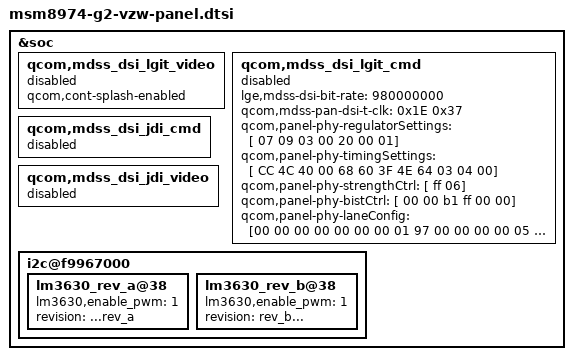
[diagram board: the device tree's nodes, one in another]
/* Copyright (c) 2012, Code Aurora Forum. All rights reserved.
 *
 * This program is free software; you can redistribute it and/or modify
 * it under the terms of the GNU General Public License version 2 and
 * only version 2 as published by the Free Software Foundation.
 *
 * This program is distributed in the hope that it will be useful,
 * but WITHOUT ANY WARRANTY; without even the implied warranty of
 * MERCHANTABILITY or FITNESS FOR A PARTICULAR PURPOSE.  See the
 * GNU General Public License for more details.
 */

&soc {
	qcom,mdss_dsi_lgit_video {
		status = "disable";
		qcom,cont-splash-enabled;
	};

	qcom,mdss_dsi_lgit_cmd {
		status = "disable";
		lge,mdss-dsi-bit-rate = <980000000>;
		qcom,mdss-pan-dsi-t-clk = <0x1E 0x37>;
		qcom,panel-phy-regulatorSettings = [
			07 09 03 00  /* Regualotor settings */
			20 00 01];
		qcom,panel-phy-timingSettings = [
			CC 4C 40 00 68 60
			3F 4E 64 03 04 00];
		qcom,panel-phy-strengthCtrl = [
			ff 06];
		qcom,panel-phy-bistCtrl = [
			00 00 b1 ff           /* BIST Ctrl settings */
			00 00];
		qcom,panel-phy-laneConfig =
			[00 00 00 00 00 00 00 01 97 /* lane0 config */
			00 00 00 00 05 00 00 01 97 /* lane1 config */
			00 00 00 00 0a 00 00 01 97 /* lane2 config */
			00 00 00 00 0f 00 00 01 97 /* lane3 config */
			00 c0 00 00 00 00 00 01 bb]; /* Clk ln config */

	};

	qcom,mdss_dsi_jdi_cmd {
		status = "disable";
	};

	qcom,mdss_dsi_jdi_video {
		status = "disable";
	};

	i2c@f9967000 {
		lm3630_rev_a@38 {
			status = "ok";
			lm3630,enable_pwm = <1>;
			revision = "...rev_a";
		};

		lm3630_rev_b@38 {
			status = "ok";
			lm3630,enable_pwm = <1>;
			revision = "rev_b...";
		};
	};
};
